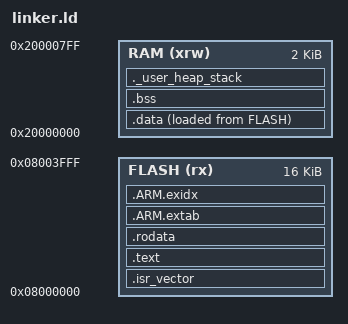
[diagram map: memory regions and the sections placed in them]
ENTRY(Reset_Handler)

MEMORY
{
  FLASH (rx) : ORIGIN = 0x08000000, LENGTH = 16K
  RAM  (xrw): ORIGIN = 0x20000000, LENGTH = 2K
}

/* 栈顶：RAM 末尾，栈向下生长 */
_estack = ORIGIN(RAM) + LENGTH(RAM);

/* 预留栈空间，用于在链接阶段检查是否溢出
 * 去掉蜂鸣器后调用链最深约 10 层 < 200B，512B 已翻倍富余 */
_Min_Stack_Size = 0x200;

SECTIONS
{
  /* ---- 中断向量表放在 Flash 开头 ---- */
  .isr_vector :
  {
    . = ALIGN(4);
    KEEP(*(.isr_vector))
    . = ALIGN(4);
  } >FLASH

  /* ---- 代码 ---- */
  .text :
  {
    . = ALIGN(4);
    *(.text)
    *(.text*)
    *(.glue_7)
    *(.glue_7t)
    *(.eh_frame)
    KEEP(*(.init))
    KEEP(*(.fini))
    . = ALIGN(4);
    _etext = .;
  } >FLASH

  /* ---- 只读数据（Font6x8 等） ---- */
  .rodata :
  {
    . = ALIGN(4);
    *(.rodata)
    *(.rodata*)
    . = ALIGN(4);
  } >FLASH

  /* ---- ARM 异常索引 ---- */
  .ARM.extab : { *(.ARM.extab* .gnu.linkonce.armextab.*) } >FLASH
  .ARM.exidx :
  {
    __exidx_start = .;
    *(.ARM.exidx* .gnu.linkonce.armexidx.*)
    __exidx_end = .;
  } >FLASH

  /* ---- .data：VMA 在 RAM，LMA 在 Flash ---- */
  _sidata = LOADADDR(.data);

  .data :
  {
    . = ALIGN(4);
    _sdata = .;
    *(.data)
    *(.data*)
    . = ALIGN(4);
    _edata = .;
  } >RAM AT> FLASH

  /* ---- .bss：清零即可，不占 Flash ---- */
  .bss :
  {
    . = ALIGN(4);
    _sbss = .;
    __bss_start__ = _sbss;
    *(.bss)
    *(.bss*)
    *(COMMON)
    . = ALIGN(4);
    _ebss = .;
    __bss_end__ = _ebss;
  } >RAM

  /* ---- 预留栈空间 ---- */
  ._user_heap_stack :
  {
    . = ALIGN(8);
    PROVIDE(end  = .);
    PROVIDE(_end = .);
    . = . + _Min_Stack_Size;
    . = ALIGN(8);
  } >RAM
}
